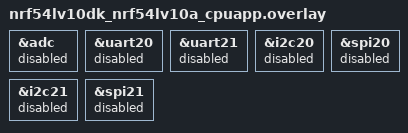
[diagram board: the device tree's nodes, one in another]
/*
 * Copyright (c) 2025 Nordic Semiconductor ASA
 *
 * SPDX-License-Identifier: LicenseRef-Nordic-5-Clause
 */

#include <state_notifier_aliases.dtsi>

&adc {
	status = "disabled";
};
&uart20 {
	status = "disabled";
};
&uart21 {
	status = "disabled";
};
&i2c20 {
	status = "disabled";
};
&spi20 {
	status = "disabled";
};
&i2c21 {
	status = "disabled";
};
&spi21 {
	status = "disabled";
};

#include <nrf54lv10_cpuapp_partitions.dtsi>
